# nrf5340_network register map
Vendor: Nordic Semiconductor; Series: nrf53; File version: 1
CPU: CM33 r0p4, little endian, MPU, no FPU, 3 interrupt priority bits, 30 interrupts
Registers are 32-bit, read-write, reset 0x0 unless marked. A register's access mark holds for its fields unless they carry their own. Offsets are from the block's base; [hi:lo] are bit positions; lines under a group give offsets from that group; 'fields as' and 'values as' point back to an identical list.

## CTRLAP_NS — Control access port
Base 0x41006000
0x400 MAILBOX group — Unspecified
  0x00 RXDATA ro — Data sent from the debugger to the CPU
    [31:0] RXDATA — Data received from debugger
  0x04 RXSTATUS ro — Status to indicate if data sent from the debugger to the CPU has been read
    [0] RXSTATUS — Status of data in register RXDATA
      0=No data pending in register RXDATA; 1=Data pending in register RXDATA
  0x80 TXDATA — Data sent from the CPU to the debugger
    [31:0] TXDATA — Data sent to debugger
  0x84 TXSTATUS ro — Status to indicate if data sent from the CPU to the debugger has been read
    [0] TXSTATUS — Status of data in register TXDATA
      0=No data pending in register TXDATA; 1=Data pending in register TXDATA
0x500 ERASEPROTECT group — Unspecified
  0x00 LOCK rw-once — Lock register ERASEPROTECT.DISABLE from being written until next reset
    [0] LOCK
      0=Unlocked (Register ERASEPROTECT.DISABLE is writeable); 1=Locked (Register ERASEPROTECT.DISABLE is read-only)
  0x04 DISABLE — Disable ERASEPROTECT and perform ERASEALL
    [31:0] KEY — The ERASEALL sequence will be initiated if value of KEY fields are non-zero and KEY fields match on both CPU and debugger side
0x540 APPROTECT group — Unspecified
  0x00 LOCK rw-once — Lock register APPROTECT.DISABLE from being written to until next reset
    [0] LOCK
      0=Unlocked (Register APPROTECT.DISABLE is writeable); 1=Locked (Register APPROTECT.DISABLE is read-only)
  0x04 DISABLE — Disable APPROTECT and enable debug access to non-secure mode
    [31:0] KEY — Disable APPROTECT and enable debug access to non-secure mode until next pin reset if KEY fields match The current APPROTECT value as configured from UICR is bypassed if value of KEY fields are non-zero and KEY fields match on both CPU and debugger side
0x548 SECUREAPPROTECT group — Unspecified
  0x00 LOCK rw-once — Lock register SECUREAPPROTECT.DISABLE from being written until next reset
    [0] LOCK
      0=Unlocked (Register SECUREAPPROTECT.DISABLE is writeable); 1=Locked (Register SECUREAPPROTECT.DISABLE is read-only)
  0x04 DISABLE — Disable SECUREAPPROTECT and enable debug access to secure mode
    [31:0] KEY — Disable SECUREAPPROTECT and enable debug of secure mode until next pin reset if KEY fields match The current SECUREAPPROTECT value as configured from UICR is bypassed if value of KEY fields are non-zero and KEY fields match on both CPU and debugger side
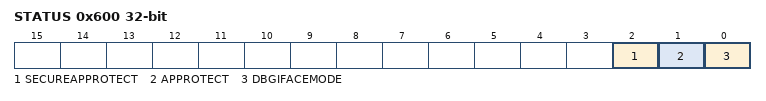
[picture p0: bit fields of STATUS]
0x600 STATUS ro — Status bits for CTRL-AP peripheral
  [2] SECUREAPPROTECT — Status bit for access port protection in secure mode
    0=Disabled (Secure mode access port protection is currently disabled); 1=Enabled (Secure mode access port protection is currently enabled)
  [1] APPROTECT — Status bit for access port protection in non-secure mode
    0=Disabled (Non-secure mode access port protection is currently disabled); 1=Enabled (Non-secure mode access port protection is currently enabled)
  [0] DBGIFACEMODE — Status bit for device debug interface mode
    0=Disabled (No debugger attached); 1=Enabled (Debugger is attached and device is in debug interface mode)

## RNG_NS — Random Number Generator
Base 0x41009000
0x00 TASKS_START wo — Task starting the random number generator
  [0] TASKS_START
    1=Trigger task
0x04 TASKS_STOP wo — Task stopping the random number generator
  [0] TASKS_STOP
    1=Trigger task
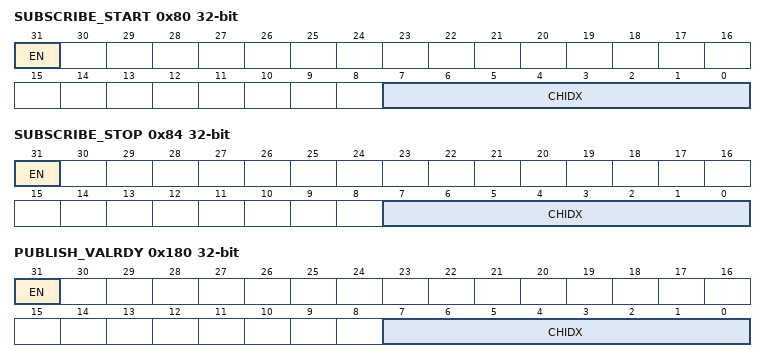
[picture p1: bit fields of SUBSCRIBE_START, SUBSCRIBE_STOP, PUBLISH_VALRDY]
0x80 SUBSCRIBE_START — Subscribe configuration for task START
  [31] EN
    0=Disabled (Disable subscription); 1=Enabled (Enable subscription)
  [7:0] CHIDX — Channel that task START will subscribe to
0x84 SUBSCRIBE_STOP — Subscribe configuration for task STOP
  [31] EN
    values as SUBSCRIBE_START.EN
  [7:0] CHIDX — Channel that task STOP will subscribe to
0x100 EVENTS_VALRDY — Event being generated for every new random number written to the VALUE register
  [0] EVENTS_VALRDY
    0=NotGenerated (Event not generated); 1=Generated (Event generated)
0x180 PUBLISH_VALRDY — Publish configuration for event VALRDY
  [31] EN
    0=Disabled (Disable publishing); 1=Enabled (Enable publishing)
  [7:0] CHIDX — Channel that event VALRDY will publish to.
0x200 SHORTS — Shortcuts between local events and tasks
  [0] VALRDY_STOP — Shortcut between event VALRDY and task STOP
    0=Disabled (Disable shortcut); 1=Enabled (Enable shortcut)
0x304 INTENSET — Enable interrupt
  [0] VALRDY — Write '1' to enable interrupt for event VALRDY
    on read: 0=Disabled (Read: Disabled); 1=Enabled (Read: Enabled) | on write: 1=Set (Enable)
0x308 INTENCLR — Disable interrupt
  [0] VALRDY — Write '1' to disable interrupt for event VALRDY
    on read: 0=Disabled (Read: Disabled); 1=Enabled (Read: Enabled) | on write: 1=Clear (Disable)
0x504 CONFIG — Configuration register
  [0] DERCEN — Bias correction
    0=Disabled; 1=Enabled
0x508 VALUE ro — Output random number
  [7:0] VALUE — Generated random number
